AUTOSAR XML (schema 4-2-2)
package /Components
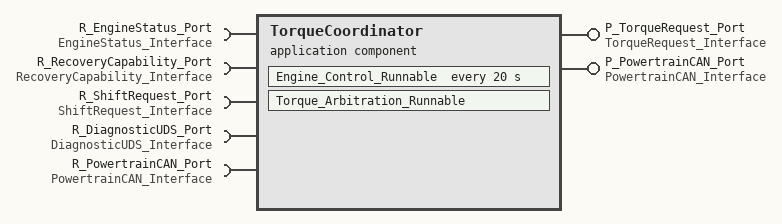
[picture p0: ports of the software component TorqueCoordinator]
  application sw component type TorqueCoordinator
    provide port P_TorqueRequest_Port: provided-interface=TorqueRequest_Interface
    provide port P_PowertrainCAN_Port: provided-interface=PowertrainCAN_Interface
    provide/require port PR_ShiftRequest_PR_Port: provided-required-interface=ShiftRequest_Interface
    5 x require port:
      R_EngineStatus_Port: required-interface=EngineStatus_Interface
      R_RecoveryCapability_Port: required-interface=RecoveryCapability_Interface
      R_ShiftRequest_Port: required-interface=ShiftRequest_Interface
      R_DiagnosticUDS_Port: required-interface=DiagnosticUDS_Interface
      R_PowertrainCAN_Port: required-interface=PowertrainCAN_Interface
    behavior TorqueCoordinatorBehavior
      external trigger occurred event Emergency_Brake_Event: start-on-event=Recovery_Evaluation_Runnable
      timing event Coordinator_Tick: start-on-event=Engine_Control_Runnable, period=20
      runnable Torque_Arbitration_Runnable: minimum-start-interval=20, symbol=TorqueCoordinator_Torque_Arbitration
        data-receive-point-by-arguments:
          access VA_EngineStatus: accessed-variable=R_EngineStatus_Port.EngineTorqueAvailable
          access VA_RecoveryCapability: accessed-variable=R_RecoveryCapability_Port.RecoveryTorqueCapability
          access VA_GearState_From_CAN: accessed-variable=R_PowertrainCAN_Port.GearState
        data-send-points:
          access VA_TorqueRequest_To_Actuators: accessed-variable=P_TorqueRequest_Port.torque
          access VA_CAN_Notification: accessed-variable=P_PowertrainCAN_Port.CAN_Frame
        async call Async_Diagnostic_Call: operation=R_DiagnosticUDS_Port.ReadDataByIdentifier, timeout=100
